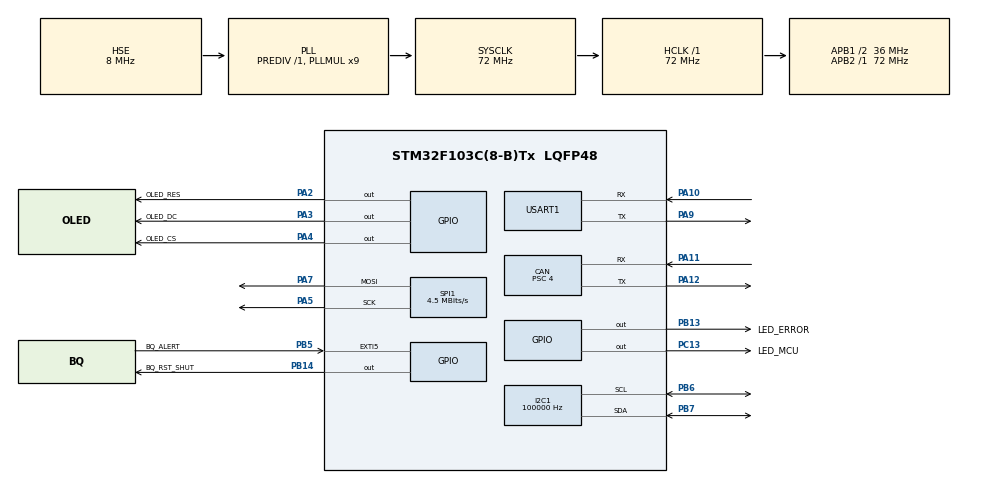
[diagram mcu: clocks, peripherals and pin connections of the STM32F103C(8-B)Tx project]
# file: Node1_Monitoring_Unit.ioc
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CAN.ABOM=ENABLE
CAN.BS1=CAN_BS1_14TQ
CAN.BS2=CAN_BS2_3TQ
CAN.CalculateBaudRate=500000
CAN.CalculateTimeBit=2000
CAN.CalculateTimeQuantum=111.11111111111111
CAN.NART=ENABLE
CAN.Prescaler=4
CAN.SJW=CAN_SJW_2TQ
CAN.TXFP=ENABLE
I2C1.ClockSpeed=100000
IWDG.Prescaler=IWDG_PRESCALER_64
IWDG.Reload=1250
Mcu.Family=STM32F1
Mcu.Name=STM32F103C(8-B)Tx
Mcu.Package=LQFP48
NVIC.CAN1_SCE_IRQn=true\:6\:0\:false\:false\:true\:true\:true\:true
NVIC.EXTI9_5_IRQn=true\:5\:0\:false\:false\:true\:true\:true\:true
NVIC.PriorityGroup=NVIC_PRIORITYGROUP_4
NVIC.USART1_IRQn=true\:10\:0\:false\:false\:true\:true\:true\:true
NVIC.USB_HP_CAN1_TX_IRQn=true\:6\:0\:false\:false\:true\:true\:true\:true
NVIC.USB_LP_CAN1_RX0_IRQn=true\:6\:0\:false\:false\:true\:true\:true\:true
PA10.Mode=Asynchronous
PA10.Signal=USART1_RX
PA11.Mode=CAN_Activate
PA11.Signal=CAN_RX
PA12.Mode=CAN_Activate
PA12.Signal=CAN_TX
PA13.Mode=Serial_Wire
PA13.Signal=SYS_JTMS-SWDIO
PA14.Mode=Serial_Wire
PA14.Signal=SYS_JTCK-SWCLK
PA2.GPIO_Label=OLED_RES
PA2.GPIO_Speed=GPIO_SPEED_FREQ_HIGH
PA2.Signal=GPIO_Output
PA3.GPIO_Label=OLED_DC
PA3.GPIO_Speed=GPIO_SPEED_FREQ_HIGH
PA3.Signal=GPIO_Output
PA4.GPIO_Label=OLED_CS
PA4.GPIO_Speed=GPIO_SPEED_FREQ_HIGH
PA4.PinState=GPIO_PIN_SET
PA4.Signal=GPIO_Output
PA5.Mode=TX_Only_Simplex_Unidirect_Master
PA5.Signal=SPI1_SCK
PA7.Mode=TX_Only_Simplex_Unidirect_Master
PA7.Signal=SPI1_MOSI
PA9.Mode=Asynchronous
PA9.Signal=USART1_TX
PB13.GPIO_Label=LED_ERROR
PB13.PinState=GPIO_PIN_SET
PB13.Signal=GPIO_Output
PB14.GPIO_Label=BQ_RST_SHUT
PB14.Signal=GPIO_Output
PB5.GPIO_Label=BQ_ALERT
PB5.GPIO_ModeDefaultEXTI=GPIO_MODE_IT_FALLING
PB5.Signal=GPXTI5
PB6.Mode=I2C
PB6.Signal=I2C1_SCL
PB7.Mode=I2C
PB7.Signal=I2C1_SDA
PC13-TAMPER-RTC.GPIO_Label=LED_MCU
PC13-TAMPER-RTC.PinState=GPIO_PIN_SET
PC13-TAMPER-RTC.Signal=GPIO_Output
PD0-OSC_IN.Mode=HSE-External-Oscillator
PD0-OSC_IN.Signal=RCC_OSC_IN
PD1-OSC_OUT.Mode=HSE-External-Oscillator
PD1-OSC_OUT.Signal=RCC_OSC_OUT
ProjectManager.HeapSize=0x200
ProjectManager.StackSize=0x800
ProjectManager.TargetToolchain=CMake
RCC.ADCPresc=RCC_ADCPCLK2_DIV2
RCC.AHBFreq_Value=72000000
RCC.APB1CLKDivider=RCC_HCLK_DIV2
RCC.APB1Freq_Value=36000000
RCC.APB1TimFreq_Value=72000000
RCC.APB2Freq_Value=72000000
RCC.APB2TimFreq_Value=72000000
RCC.HCLKFreq_Value=72000000
RCC.PLLMUL=RCC_PLL_MUL9
RCC.PLLSourceVirtual=RCC_PLLSOURCE_HSE
RCC.SYSCLKFreq_VALUE=72000000
RCC.SYSCLKSource=RCC_SYSCLKSOURCE_PLLCLK
RCC.USBFreq_Value=72000000
SPI1.BaudRatePrescaler=SPI_BAUDRATEPRESCALER_16
SPI1.CalculateBaudRate=4.5 MBits/s
SPI1.Direction=SPI_DIRECTION_2LINES
SPI1.Mode=SPI_MODE_MASTER
SPI1.VirtualType=VM_MASTER
USART1.VirtualMode=VM_ASYNC
VP_IWDG_VS_IWDG.Mode=IWDG_Activate
board=custom

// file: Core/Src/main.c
/* USER CODE BEGIN Header */
/**
  ******************************************************************************
  * @file           : main.c
  * @brief          : Distributed BMS - Node 1 Master Monitoring Unit
  *                   STM32F103C8T6 + BQ76952 (16S) + ISO1042 CAN + SSD1306
  *
  *  Peripheral set-up is generated by STM32CubeMX (Node1_Monitoring_Unit.ioc).
  *  All application code lives in App/ and is called from the USER CODE
  *  sections below, so the project can be regenerated safely.
  ******************************************************************************
  */
/* USER CODE END Header */
#include "main.h"

/* USER CODE BEGIN Includes */
#include "bms_app.h"
/* USER CODE END Includes */

CAN_HandleTypeDef hcan;

I2C_HandleTypeDef hi2c1;

IWDG_HandleTypeDef hiwdg;

SPI_HandleTypeDef hspi1;

UART_HandleTypeDef huart1;

void SystemClock_Config(void);
static void MX_GPIO_Init(void);
static void MX_CAN_Init(void);
static void MX_I2C1_Init(void);
static void MX_SPI1_Init(void);
static void MX_USART1_UART_Init(void);
static void MX_IWDG_Init(void);

int main(void)
{

  /* MCU Configuration--------------------------------------------------------*/

  /* Reset of all peripherals, Initializes the Flash interface and the Systick. */
  HAL_Init();

  /* Configure the system clock */
  SystemClock_Config();

  /* Initialize all configured peripherals */
  MX_GPIO_Init();
  MX_CAN_Init();
  MX_I2C1_Init();
  MX_SPI1_Init();
  MX_USART1_UART_Init();
  /* USER CODE BEGIN 2 */
  BMS_App_Init(&hi2c1, &hcan, &hspi1, &huart1, &hiwdg);
#if (BMS_USE_IWDG == 1)
  /* Started after the first BQ76952 bring-up, which can take ~1 s. */
  MX_IWDG_Init();
#endif
  /* USER CODE END 2 */

  /* Infinite loop */
  while (1)
  {

    /* USER CODE BEGIN 3 */
    BMS_App_Loop();
  }
  /* USER CODE END 3 */
}

void SystemClock_Config(void)
{
  RCC_OscInitTypeDef RCC_OscInitStruct = {0};
  RCC_ClkInitTypeDef RCC_ClkInitStruct = {0};

  /** Initializes the RCC Oscillators according to the specified parameters
  * in the RCC_OscInitTypeDef structure.
  */
  RCC_OscInitStruct.OscillatorType = RCC_OSCILLATORTYPE_LSI|RCC_OSCILLATORTYPE_HSE;
  RCC_OscInitStruct.HSEState = RCC_HSE_ON;
  RCC_OscInitStruct.HSEPredivValue = RCC_HSE_PREDIV_DIV1;
  RCC_OscInitStruct.HSIState = RCC_HSI_ON;
  RCC_OscInitStruct.LSIState = RCC_LSI_ON;
  RCC_OscInitStruct.PLL.PLLState = RCC_PLL_ON;
  RCC_OscInitStruct.PLL.PLLSource = RCC_PLLSOURCE_HSE;
  RCC_OscInitStruct.PLL.PLLMUL = RCC_PLL_MUL9;
  if (HAL_RCC_OscConfig(&RCC_OscInitStruct) != HAL_OK)
  {
    Error_Handler();
  }

  /** Initializes the CPU, AHB and APB buses clocks
  */
  RCC_ClkInitStruct.ClockType = RCC_CLOCKTYPE_HCLK|RCC_CLOCKTYPE_SYSCLK
                              |RCC_CLOCKTYPE_PCLK1|RCC_CLOCKTYPE_PCLK2;
  RCC_ClkInitStruct.SYSCLKSource = RCC_SYSCLKSOURCE_PLLCLK;
  RCC_ClkInitStruct.AHBCLKDivider = RCC_SYSCLK_DIV1;
  RCC_ClkInitStruct.APB1CLKDivider = RCC_HCLK_DIV2;
  RCC_ClkInitStruct.APB2CLKDivider = RCC_HCLK_DIV1;

  if (HAL_RCC_ClockConfig(&RCC_ClkInitStruct, FLASH_LATENCY_2) != HAL_OK)
  {
    Error_Handler();
  }
}

static void MX_CAN_Init(void)
{

  hcan.Instance = CAN1;
  hcan.Init.Prescaler = 4;
  hcan.Init.Mode = CAN_MODE_NORMAL;
  hcan.Init.SyncJumpWidth = CAN_SJW_2TQ;
  hcan.Init.TimeSeg1 = CAN_BS1_14TQ;
  hcan.Init.TimeSeg2 = CAN_BS2_3TQ;
  hcan.Init.TimeTriggeredMode = DISABLE;
  hcan.Init.AutoBusOff = ENABLE;
  hcan.Init.AutoWakeUp = DISABLE;
  hcan.Init.AutoRetransmission = ENABLE;
  hcan.Init.ReceiveFifoLocked = DISABLE;
  hcan.Init.TransmitFifoPriority = ENABLE;
  if (HAL_CAN_Init(&hcan) != HAL_OK)
  {
    Error_Handler();
  }

}

static void MX_I2C1_Init(void)
{

  hi2c1.Instance = I2C1;
  hi2c1.Init.ClockSpeed = 100000;
  hi2c1.Init.DutyCycle = I2C_DUTYCYCLE_2;
  hi2c1.Init.OwnAddress1 = 0;
  hi2c1.Init.AddressingMode = I2C_ADDRESSINGMODE_7BIT;
  hi2c1.Init.DualAddressMode = I2C_DUALADDRESS_DISABLE;
  hi2c1.Init.OwnAddress2 = 0;
  hi2c1.Init.GeneralCallMode = I2C_GENERALCALL_DISABLE;
  hi2c1.Init.NoStretchMode = I2C_NOSTRETCH_DISABLE;
  if (HAL_I2C_Init(&hi2c1) != HAL_OK)
  {
    Error_Handler();
  }

}

static void MX_IWDG_Init(void)
{

  hiwdg.Instance = IWDG;
  hiwdg.Init.Prescaler = IWDG_PRESCALER_64;
  hiwdg.Init.Reload = 1250;
  if (HAL_IWDG_Init(&hiwdg) != HAL_OK)
  {
    Error_Handler();
  }

}

static void MX_SPI1_Init(void)
{

  /* SPI1 parameter configuration*/
  hspi1.Instance = SPI1;
  hspi1.Init.Mode = SPI_MODE_MASTER;
  hspi1.Init.Direction = SPI_DIRECTION_2LINES;
  hspi1.Init.DataSize = SPI_DATASIZE_8BIT;
  hspi1.Init.CLKPolarity = SPI_POLARITY_LOW;
  hspi1.Init.CLKPhase = SPI_PHASE_1EDGE;
  hspi1.Init.NSS = SPI_NSS_SOFT;
  hspi1.Init.BaudRatePrescaler = SPI_BAUDRATEPRESCALER_16;
  hspi1.Init.FirstBit = SPI_FIRSTBIT_MSB;
  hspi1.Init.TIMode = SPI_TIMODE_DISABLE;
  hspi1.Init.CRCCalculation = SPI_CRCCALCULATION_DISABLE;
  hspi1.Init.CRCPolynomial = 10;
  if (HAL_SPI_Init(&hspi1) != HAL_OK)
  {
    Error_Handler();
  }

}

static void MX_USART1_UART_Init(void)
{

  huart1.Instance = USART1;
  huart1.Init.BaudRate = 115200;
  huart1.Init.WordLength = UART_WORDLENGTH_8B;
  huart1.Init.StopBits = UART_STOPBITS_1;
  huart1.Init.Parity = UART_PARITY_NONE;
  huart1.Init.Mode = UART_MODE_TX_RX;
  huart1.Init.HwFlowCtl = UART_HWCONTROL_NONE;
  huart1.Init.OverSampling = UART_OVERSAMPLING_16;
  if (HAL_UART_Init(&huart1) != HAL_OK)
  {
    Error_Handler();
  }

}

static void MX_GPIO_Init(void)
{
  GPIO_InitTypeDef GPIO_InitStruct = {0};

  /* GPIO Ports Clock Enable */
  __HAL_RCC_GPIOC_CLK_ENABLE();
  __HAL_RCC_GPIOD_CLK_ENABLE();
  __HAL_RCC_GPIOA_CLK_ENABLE();
  __HAL_RCC_GPIOB_CLK_ENABLE();

  /*Configure GPIO pin Output Level */
  HAL_GPIO_WritePin(LED_MCU_GPIO_Port, LED_MCU_Pin, GPIO_PIN_SET);

  /*Configure GPIO pin Output Level */
  HAL_GPIO_WritePin(GPIOA, OLED_RES_Pin|OLED_DC_Pin, GPIO_PIN_RESET);

  /*Configure GPIO pin Output Level */
  HAL_GPIO_WritePin(OLED_CS_GPIO_Port, OLED_CS_Pin, GPIO_PIN_SET);

  /*Configure GPIO pin Output Level */
  HAL_GPIO_WritePin(LED_ERROR_GPIO_Port, LED_ERROR_Pin, GPIO_PIN_SET);

  /*Configure GPIO pin Output Level */
  HAL_GPIO_WritePin(BQ_RST_SHUT_GPIO_Port, BQ_RST_SHUT_Pin, GPIO_PIN_RESET);

  /*Configure GPIO pin : LED_MCU_Pin */
  GPIO_InitStruct.Pin = LED_MCU_Pin;
  GPIO_InitStruct.Mode = GPIO_MODE_OUTPUT_PP;
  GPIO_InitStruct.Pull = GPIO_NOPULL;
  GPIO_InitStruct.Speed = GPIO_SPEED_FREQ_LOW;
  HAL_GPIO_Init(LED_MCU_GPIO_Port, &GPIO_InitStruct);

  /*Configure GPIO pins : OLED_RES_Pin OLED_DC_Pin OLED_CS_Pin */
  GPIO_InitStruct.Pin = OLED_RES_Pin|OLED_DC_Pin|OLED_CS_Pin;
  GPIO_InitStruct.Mode = GPIO_MODE_OUTPUT_PP;
  GPIO_InitStruct.Pull = GPIO_NOPULL;
  GPIO_InitStruct.Speed = GPIO_SPEED_FREQ_HIGH;
  HAL_GPIO_Init(GPIOA, &GPIO_InitStruct);

  /*Configure GPIO pins : LED_ERROR_Pin BQ_RST_SHUT_Pin */
  GPIO_InitStruct.Pin = LED_ERROR_Pin|BQ_RST_SHUT_Pin;
  GPIO_InitStruct.Mode = GPIO_MODE_OUTPUT_PP;
  GPIO_InitStruct.Pull = GPIO_NOPULL;
  GPIO_InitStruct.Speed = GPIO_SPEED_FREQ_LOW;
  HAL_GPIO_Init(GPIOB, &GPIO_InitStruct);

  /*Configure GPIO pin : BQ_ALERT_Pin */
  GPIO_InitStruct.Pin = BQ_ALERT_Pin;
  GPIO_InitStruct.Mode = GPIO_MODE_IT_FALLING;
  GPIO_InitStruct.Pull = GPIO_NOPULL;
  HAL_GPIO_Init(BQ_ALERT_GPIO_Port, &GPIO_InitStruct);

  /* EXTI interrupt init*/
  HAL_NVIC_SetPriority(EXTI9_5_IRQn, 5, 0);
  HAL_NVIC_EnableIRQ(EXTI9_5_IRQn);

}

/* USER CODE BEGIN 4 */

void HAL_GPIO_EXTI_Callback(uint16_t GPIO_Pin)
{
  if (GPIO_Pin == BQ_ALERT_Pin)
  {
    BMS_App_OnAlertIrq();
  }
}

/* USER CODE END 4 */

void Error_Handler(void)
{
  /* USER CODE BEGIN Error_Handler_Debug */
  /* Only reached if clock or peripheral initialisation fails. The MCU stops
   * talking on CAN, so the System Controller trips on heartbeat loss. */
  __disable_irq();
  HAL_GPIO_WritePin(LED_ERROR_GPIO_Port, LED_ERROR_Pin, GPIO_PIN_RESET);
  while (1)
  {
  }
  /* USER CODE END Error_Handler_Debug */
}
